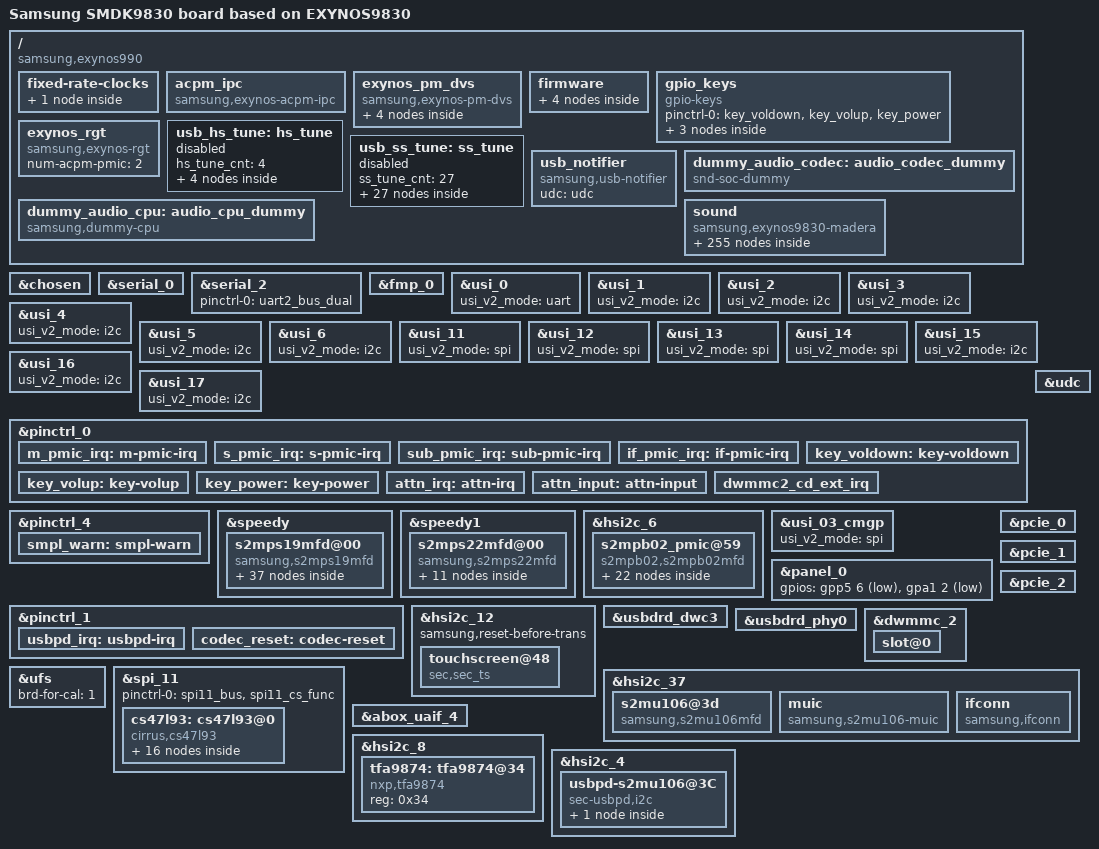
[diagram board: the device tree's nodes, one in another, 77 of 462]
/*
 * SAMSUNG EXYNOS9830 board device tree source
 *
 * Copyright (c) 2016 Samsung Electronics Co., Ltd.
 *		http://www.samsung.com
 *
 * This program is free software; you can redistribute it and/or modify
 * it under the terms of the GNU General Public License version 2 as
 * published by the Free Software Foundation.
*/

/dts-v1/;
/plugin/;
#include <dt-bindings/clock/exynos9830.h>
#include <dt-bindings/display/exynos-display.h>
#include "exynos9830-display-lcd.dtsi"
#include <dt-bindings/pci/pci.h>
#include "exynos9830-smdk9830-camera.dtsi"

#define BOARD_ID	0x0
#define BOARD_REV	0x0

/ {
	compatible = "samsung,exynos990", "samsung,SMDK990";
	board_id = <BOARD_ID>;
	board_rev = <BOARD_REV>;

	fragment@model {
		target-path = "/";
		__overlay__ {
			#address-cells = <2>;
			#size-cells = <1>;

			model = "Samsung SMDK9830 board based on EXYNOS9830";

			fixed-rate-clocks {
				oscclk {
					compatible = "samsung,exynos9830-oscclk";
					clock-frequency = <26000000>;
				};
			};

			acpm_ipc {
				compatible = "samsung,exynos-acpm-ipc";
				board-id = <BOARD_ID>;
				board-rev = <BOARD_REV>;
			};

			exynos_pm_dvs {
				compatible = "samsung,exynos-pm-dvs";
				vdd_lldo1 {
					regulator_name = "m_vdd_buck9";
					suspend_volt = <800000>;
					init_volt = <850000>;
					volt_range_step = <62500>;
				};

				vdd_lldo2 {
					regulator_name = "m_vdd_buck10";
					suspend_volt = <900000>;
					init_volt = <950000>;
					volt_range_step = <62500>;
				};

				vdd_lldo3 {
					regulator_name = "m_vdd_buck11";
					suspend_volt = <1250000>;
					init_volt = <1350000>;
					volt_range_step = <62500>;
				};
				vdd_mldo {
					regulator_name = "m_vdd_buck12";
					suspend_volt = <1850000>;
					init_volt = <2000000>;
					volt_range_step = <12500>;
				};
			};

			firmware {
				android: android {
					compatible = "android,firmware";
					vbmeta {
						compatible = "android,vbmeta";
						parts = "vbmeta,boot,system,vendor";
					};
					fstab {
						compatible = "android,fstab";
						vendor: vendor {
							compatible = "android,vendor";
							dev = "/dev/block/platform/13100000.ufs/by-name/vendor";
							type = "ext4";
							mnt_flags = "ro";
							fsmgr_flags = "wait,avb";
							status = "okay";
						};
					};
				};
			};

			gpio_keys {
				status = "okay";
				compatible = "gpio-keys";
				pinctrl-names = "default";
				pinctrl-0 = <&key_voldown &key_volup &key_power>;

				button@2 {
					label = "gpio-keys: KEY_VOLUMEDOWN";
					linux,code = <114>;
					gpios = <&gpa0 4 0xf>;
				};
				button@3 {
					label = "gpio-keys: KEY_VOLUMEUP";
					linux,code = <115>;
					gpios = <&gpa0 3 0xf>;
				};
				button@4 {
					label = "gpio-keys: KEY_POWER";
					linux,code = <116>;
					gpios = <&gpa2 4 0xf>;
					gpio-key,wakeup = <1>;
				};
			};

			exynos_rgt {
				compatible = "samsung,exynos-rgt";
				num-acpm-pmic = <2>;
			};

			usb_hs_tune:hs_tune {
				status = "disabled";
				hs_tune_cnt = <4>;
				/* value = <device host> */
				hs_tune1 {
					tune_name = "tx_pre_emp";
					tune_value = <0x3 0x3>;
				};

				hs_tune2 {
					tune_name = "tx_vref";
					tune_value = <0xc 0xc>;
				};

				hs_tune3 {
					tune_name = "rx_sqrx";
					tune_value = <0x5 0x5>;
				};

				hs_tune4 {
					tune_name = "utmi_clk";
					tune_value = <0x1 0x1>;
				};
			};

			usb_ss_tune:ss_tune {
				status = "disabled";
				ss_tune_cnt = <27>;
				/* value = <device host> */
				ss_tune1 {
					tune_name = "ssrx_sqhs_th_ssp";
					tune_value = <0x4 0x4>;
				};

				ss_tune2 {
					tune_name = "ssrx_lfps_th";
					tune_value = <0x2 0x2>;
				};

				ss_tune3 {
					tune_name = "ssrx_adap_coef_sel";
					tune_value = <0x1 0x1>;
				};

				ss_tune4 {
					tune_name = "ssrx_mf_eq_ctrl_ss";
					tune_value = <0x6 0x6>;
				};

				ss_tune5 {
					tune_name = "ssrx_mf_eq_ctrl_ssp";
					tune_value = <0x6 0x6>;
				};

				ss_tune6 {
					tune_name = "ssrx_hf_eq_ctrl_ss";
					tune_value = <0xe 0xe>;
				};

				ss_tune7 {
					tune_name = "ssrx_hf_eq_ctrl_ssp";
					tune_value = <0xe 0xe>;
				};

				ss_tune8 {
					tune_name = "ssrx_dfe_1tap_ctrl_ss";
					tune_value = <0x2 0x2>;
				};

				ss_tune9 {
					tune_name = "ssrx_dfe_1tap_ctrl_ssp";
					tune_value = <0x2 0x2>;
				};

				ss_tune10 {
					tune_name = "ssrx_dfe_2tap_ctrl_ss";
					tune_value = <0x0 0x0>;
				};

				ss_tune11 {
					tune_name = "ssrx_dfe_2tap_ctrl_ssp";
					tune_value = <0x0 0x0>;
				};

				ss_tune12 {
					tune_name = "ssrx_dfe_3tap_ctrl_ss";
					tune_value = <0x0 0x0>;
				};

				ss_tune13 {
					tune_name = "ssrx_dfe_3tap_ctrl_ssp";
					tune_value = <0x0 0x0>;
				};

				ss_tune14 {
					tune_name = "ssrx_dfe_4tap_ctrl_ss";
					tune_value = <0x0 0x0>;
				};

				ss_tune15 {
					tune_name = "ssrx_dfe_4tap_ctrl_ssp";
					tune_value = <0x0 0x0>;
				};

				ss_tune16 {
					tune_name = "ssrx_term_cal";
					tune_value = <0xb 0xb>;
				};

				ss_tune17 {
					tune_name = "sstx_amp_ss";
					tune_value = <0xb 0xb>;
				};

				ss_tune18 {
					tune_name = "sstx_deemp_ss";
					tune_value = <0x5 0x5>;
				};

				ss_tune19 {
					tune_name = "sstx_pre_shoot_ss";
					tune_value = <0x3 0x3>;
				};

				ss_tune20 {
					tune_name = "sstx_amp_ssp";
					tune_value = <0xb 0xb>;
				};

				ss_tune21 {
					tune_name = "sstx_deemp_ssp";
					tune_value = <0x5 0x5>;
				};

				ss_tune22 {
					tune_name = "sstx_pre_shoot_ssp";
					tune_value = <0x3 0x3>;
				};

				ss_tune23 {
					tune_name = "sstx_idrv_up";
					tune_value = <0x7 0x7>;
				};

				ss_tune24 {
					tune_name = "sstx_lfps_idrv_up";
					tune_value = <0x0 0x0>;
				};

				ss_tune25 {
					tune_name = "sstx_up_term";
					tune_value = <0x3 0x3>;
				};

				ss_tune26 {
					tune_name = "sstx_dn_term";
					tune_value = <0x3 0x3>;
				};

				ss_tune27 {
					tune_name = "rext_ovrd";
					tune_value = <0x0 0x0>; /* Use default */
				};
			};

			usb_notifier {
				compatible = "samsung,usb-notifier";
				udc = <&udc>;
			};

			dummy_audio_codec: audio_codec_dummy {
				compatible = "snd-soc-dummy";
				#sound-dai-cells = <0>;
			};

			dummy_audio_cpu: audio_cpu_dummy {
				compatible = "samsung,dummy-cpu";
				#sound-dai-cells = <0>;
			};

			sound {
				compatible = "samsung,exynos9830-madera";

				clock-names = "xclkout";
				clocks = <&clock OSC_AUD>;

				cirrus,sysclk = <1 4 98304000>;
				cirrus,dspclk = <8 4 147456000>;
				cirrus,fll1-refclk = <1 0 26000000 98304000>;

				cirrus,asyncclk = <2 5 90316800>;
				cirrus,fll2-refclk = <2 0 26000000 90316800>;

				samsung,routing = "HEADSETMIC", "MICBIAS2A",
					"IN1BL", "HEADSETMIC",
					"DMIC1", "MICBIAS1A",
					"IN3L", "DMIC1",
					"DMIC2", "MICBIAS1B",
					"IN4L", "DMIC2",
					"DMIC3", "MICBIAS1C",
					"IN2AL", "DMIC3",
					"DMIC4", "MICBIAS1D",
					"IN3R", "DMIC4",
					"RECEIVER", "HPOUT4L",
					"RECEIVER", "HPOUT4R",
					"HEADPHONE", "HPOUT2L",
					"HEADPHONE", "HPOUT2R",
					"SPEAKER", "OUTL",
					"AEC Loopback", "SPEAKER FB",
					"BLUETOOTH SPK", "ABOX UAIF3 Playback",
					"ABOX UAIF3 Capture", "BLUETOOTH MIC",
					"VOUTPUT", "ABOX UAIF5 Playback",
					"USB SPK", "ABOX USB Playback",
					"ABOX USB Capture", "USB MIC",
					"VTS Virtual Output", "VTS Virtual Output Mux",
					"PAD DPDM", "DMIC1",
					"PAD DPDM", "DMIC2",
					"PAD DPDM", "DMIC3",
					"PAD DPDM", "DMIC4";
				samsung,codec = <&vts>;
				samsung,prefix = "VTS";
				samsung,aux = <&abox_effect &abox_tplg>;

				rdma0 {
					cpu {
						sound-dai = <&abox_rdma_0 0>;
					};
					platform {
						sound-dai = <&abox_rdma_0 0>;
					};
					codec {
						sound-dai = <&dummy_audio_codec>;
					};
				};
				rdma1 {
					cpu {
						sound-dai = <&abox_rdma_1 0>;
					};
					platform {
						sound-dai = <&abox_rdma_1 0>;
					};
					codec {
						sound-dai = <&dummy_audio_codec>;
					};
				};
				rdma2 {
					cpu {
						sound-dai = <&abox_rdma_2 0>;
					};
					platform {
						sound-dai = <&abox_rdma_2 0>;
					};
					codec {
						sound-dai = <&dummy_audio_codec>;
					};
				};
				rdma3 {
					cpu {
						sound-dai = <&abox_rdma_3 0>;
					};
					platform {
						sound-dai = <&abox_rdma_3 0>;
					};
					codec {
						sound-dai = <&dummy_audio_codec>;
					};
				};
				rdma4 {
					cpu {
						sound-dai = <&abox_rdma_4 0>;
					};
					platform {
						sound-dai = <&abox_rdma_4 0>;
					};
					codec {
						sound-dai = <&dummy_audio_codec>;
					};
				};
				rdma5 {
					cpu {
						sound-dai = <&abox_rdma_5 0>;
					};
					platform {
						sound-dai = <&abox_rdma_5 0>;
					};
					codec {
						sound-dai = <&dummy_audio_codec>;
					};
				};
				rdma6 {
					cpu {
						sound-dai = <&abox_rdma_6 0>;
					};
					platform {
						sound-dai = <&abox_rdma_6 0>;
					};
					codec {
						sound-dai = <&dummy_audio_codec>;
					};
				};
				rdma7 {
					cpu {
						sound-dai = <&abox_rdma_7 0>;
					};
					platform {
						sound-dai = <&abox_rdma_7 0>;
					};
					codec {
						sound-dai = <&dummy_audio_codec>;
					};
				};
				rdma8 {
					cpu {
						sound-dai = <&abox_rdma_8 0>;
					};
					platform {
						sound-dai = <&abox_rdma_8 0>;
					};
					codec {
						sound-dai = <&dummy_audio_codec>;
					};
				};
				rdma9 {
					cpu {
						sound-dai = <&abox_rdma_9 0>;
					};
					platform {
						sound-dai = <&abox_rdma_9 0>;
					};
					codec {
						sound-dai = <&dummy_audio_codec>;
					};
				};
				rdma10 {
					cpu {
						sound-dai = <&abox_rdma_10 0>;
					};
					platform {
						sound-dai = <&abox_rdma_10 0>;
					};
					codec {
						sound-dai = <&dummy_audio_codec>;
					};
				};
				rdma11 {
					cpu {
						sound-dai = <&abox_rdma_11 0>;
					};
					platform {
						sound-dai = <&abox_rdma_11 0>;
					};
					codec {
						sound-dai = <&dummy_audio_codec>;
					};
				};
				wdma0 {
					cpu {
						sound-dai = <&abox_wdma_0 0>;
					};
					platform {
						sound-dai = <&abox_wdma_0 0>;
					};
					codec {
						sound-dai = <&dummy_audio_codec>;
					};
				};
				wdma1 {
					cpu {
						sound-dai = <&abox_wdma_1 0>;
					};
					platform {
						sound-dai = <&abox_wdma_1 0>;
					};
					codec {
						sound-dai = <&dummy_audio_codec>;
					};
				};
				wdma2 {
					cpu {
						sound-dai = <&abox_wdma_2 0>;
					};
					platform {
						sound-dai = <&abox_wdma_2 0>;
					};
					codec {
						sound-dai = <&dummy_audio_codec>;
					};
				};
				wdma3 {
					cpu {
						sound-dai = <&abox_wdma_3 0>;
					};
					platform {
						sound-dai = <&abox_wdma_3 0>;
					};
					codec {
						sound-dai = <&dummy_audio_codec>;
					};
				};
				wdma4 {
					cpu {
						sound-dai = <&abox_wdma_4 0>;
					};
					platform {
						sound-dai = <&abox_wdma_4 0>;
					};
					codec {
						sound-dai = <&dummy_audio_codec>;
					};
				};
				vts0 {
					cpu {
						sound-dai = <&vts 0>;
					};
					codec {
						sound-dai = <&dummy_audio_codec>;
					};
				};
				vts1 {
					cpu {
						sound-dai = <&vts 1>;
					};
					codec {
						sound-dai = <&dummy_audio_codec>;
					};
				};
				dp0_audio {
					cpu {
						sound-dai = <&displayport_adma 0>;
					};
					codec {
						sound-dai = <&dummy_audio_codec>;
					};
				};
				dp1_audio {
					cpu {
						sound-dai = <&displayport_adma 1 >;
					};
					codec {
						sound-dai = <&dummy_audio_codec>;
					};
				};
				dual0 {
					cpu {
						sound-dai = <&abox_dual_0>;
					};
					platform {
						sound-dai = <&abox_dual_0>;
					};
					codec {
						sound-dai = <&dummy_audio_codec>;
					};
				};
				dual1 {
					cpu {
						sound-dai = <&abox_dual_1>;
					};
					platform {
						sound-dai = <&abox_dual_1>;
					};
					codec {
						sound-dai = <&dummy_audio_codec>;
					};
				};
				dual2 {
					cpu {
						sound-dai = <&abox_dual_2>;
					};
					platform {
						sound-dai = <&abox_dual_2>;
					};
					codec {
						sound-dai = <&dummy_audio_codec>;
					};
				};
				dual3 {
					cpu {
						sound-dai = <&abox_dual_3>;
					};
					platform {
						sound-dai = <&abox_dual_3>;
					};
					codec {
						sound-dai = <&dummy_audio_codec>;
					};
				};
				dual4 {
					cpu {
						sound-dai = <&abox_dual_4>;
					};
					platform {
						sound-dai = <&abox_dual_4>;
					};
					codec {
						sound-dai = <&dummy_audio_codec>;
					};
				};
				ddma0 {
					cpu {
						sound-dai = <&abox_ddma_0>;
					};
					platform {
						sound-dai = <&abox_ddma_0>;
					};
					codec {
						sound-dai = <&dummy_audio_codec>;
					};
				};
				ddma1 {
					cpu {
						sound-dai = <&abox_ddma_1>;
					};
					platform {
						sound-dai = <&abox_ddma_1>;
					};
					codec {
						sound-dai = <&dummy_audio_codec>;
					};
				};
				ddma2 {
					cpu {
						sound-dai = <&abox_ddma_2>;
					};
					platform {
						sound-dai = <&abox_ddma_2>;
					};
					codec {
						sound-dai = <&dummy_audio_codec>;
					};
				};
				ddma3 {
					cpu {
						sound-dai = <&abox_ddma_3>;
					};
					platform {
						sound-dai = <&abox_ddma_3>;
					};
					codec {
						sound-dai = <&dummy_audio_codec>;
					};
				};
				ddma4 {
					cpu {
						sound-dai = <&abox_ddma_4>;
					};
					platform {
						sound-dai = <&abox_ddma_4>;
					};
					codec {
						sound-dai = <&dummy_audio_codec>;
					};
				};
				ddma5 {
					cpu {
						sound-dai = <&abox_ddma_5>;
					};
					platform {
						sound-dai = <&abox_ddma_5>;
					};
					codec {
						sound-dai = <&dummy_audio_codec>;
					};
				};
				uaif0 {
					format = "i2s";
					cpu {
						sound-dai = <&abox_uaif_0>;
					};
					codec {
						sound-dai = <&cs47l93 0>;
					};
				};
				uaif1 {
					format = "i2s";
					cpu {
						sound-dai = <&abox_uaif_1>;
					};
					codec {
						sound-dai = <&cs47l93 2>;
					};
				};
				uaif2 {
					format = "i2s";
					cpu {
						sound-dai = <&abox_uaif_2>;
					};
					codec {
						sound-dai = <&tfa9874 0>;
					};
				};
				uaif3 {
					format = "i2s";
					cpu {
						sound-dai = <&abox_uaif_3>;
					};
					codec {
						sound-dai = <&dummy_audio_codec>;
					};
				};
				uaif4 {
					format = "i2s";
					cpu {
						sound-dai = <&abox_uaif_4>;
					};
					codec {
						sound-dai = <&dummy_audio_codec>;
					};
				};
				uaif5 {
					format = "dsp_a";
					cpu {
						sound-dai = <&abox_uaif_5>;
					};
					codec {
						sound-dai = <&dummy_audio_codec>;
					};
				};
				uaif6 {
					format = "dsp_a";
					bitclock-master;
					bitclock-inversion;
					frame-master;

					cpu {
						sound-dai = <&abox_uaif_6>;
					};
					codec {
						sound-dai = <&vts_s_lif 0>;
					};
				};
				dsif0 {
					format = "pdm";
					cpu {
						sound-dai = <&abox_dsif>;
					};
					codec {
						sound-dai = <&dummy_audio_codec>;
					};
				};
				sifs0 {
					cpu {
						sound-dai = <&abox 0>;
					};
					codec {
						sound-dai = <&dummy_audio_codec>;
					};
				};
				sifs1 {
					cpu {
						sound-dai = <&abox 1>;
					};
					codec {
						sound-dai = <&dummy_audio_codec>;
					};
				};
				sifs2 {
					cpu {
						sound-dai = <&abox 2>;
					};
					codec {
						sound-dai = <&dummy_audio_codec>;
					};
				};
				sifs3 {
					cpu {
						sound-dai = <&abox 3>;
					};
					codec {
						sound-dai = <&dummy_audio_codec>;
					};
				};
				sifs4 {
					cpu {
						sound-dai = <&abox 4>;
					};
					codec {
						sound-dai = <&dummy_audio_codec>;
					};
				};
				sifs5 {
					cpu {
						sound-dai = <&abox 5>;
					};
					codec {
						sound-dai = <&dummy_audio_codec>;
					};
				};
				nsrc0 {
					cpu {
						sound-dai = <&abox 6>;
					};
					codec {
						sound-dai = <&dummy_audio_codec>;
					};
				};
				nsrc1 {
					cpu {
						sound-dai = <&abox 7>;
					};
					codec {
						sound-dai = <&dummy_audio_codec>;
					};
				};
				nsrc2 {
					cpu {
						sound-dai = <&abox 8>;
					};
					codec {
						sound-dai = <&dummy_audio_codec>;
					};
				};
				nsrc3 {
					cpu {
						sound-dai = <&abox 9>;
					};
					codec {
						sound-dai = <&dummy_audio_codec>;
					};
				};
				nsrc4 {
					cpu {
						sound-dai = <&abox 10>;
					};
					codec {
						sound-dai = <&dummy_audio_codec>;
					};
				};
				rdma0_be {
					cpu {
						sound-dai = <&abox_rdma_0 1>;
					};
					platform {
						sound-dai = <&abox_rdma_0 1>;
					};
					codec {
						sound-dai = <&dummy_audio_codec>;
					};
				};
				rdma1_be {
					cpu {
						sound-dai = <&abox_rdma_1 1>;
					};
					platform {
						sound-dai = <&abox_rdma_1 1>;
					};
					codec {
						sound-dai = <&dummy_audio_codec>;
					};
				};
				rdma2_be {
					cpu {
						sound-dai = <&abox_rdma_2 1>;
					};
					platform {
						sound-dai = <&abox_rdma_2 1>;
					};
					codec {
						sound-dai = <&dummy_audio_codec>;
					};
				};
				rdma3_be {
					cpu {
						sound-dai = <&abox_rdma_3 1>;
					};
					platform {
						sound-dai = <&abox_rdma_3 1>;
					};
					codec {
						sound-dai = <&dummy_audio_codec>;
					};
				};
				rdma4_be {
					cpu {
						sound-dai = <&abox_rdma_4 1>;
					};
					platform {
						sound-dai = <&abox_rdma_4 1>;
					};
					codec {
						sound-dai = <&dummy_audio_codec>;
					};
				};
				rdma5_be {
					cpu {
						sound-dai = <&abox_rdma_5 1>;
					};
					platform {
						sound-dai = <&abox_rdma_5 1>;
					};
					codec {
						sound-dai = <&dummy_audio_codec>;
					};
				};
				rdma6_be {
					cpu {
						sound-dai = <&abox_rdma_6 1>;
					};
					platform {
						sound-dai = <&abox_rdma_6 1>;
					};
					codec {
						sound-dai = <&dummy_audio_codec>;
					};
				};
				rdma7_be {
					cpu {
						sound-dai = <&abox_rdma_7 1>;
					};
					platform {
						sound-dai = <&abox_rdma_7 1>;
					};
					codec {
						sound-dai = <&dummy_audio_codec>;
					};
				};
				rdma8_be {
					cpu {
						sound-dai = <&abox_rdma_8 1>;
					};
					platform {
						sound-dai = <&abox_rdma_8 1>;
					};
					codec {
						sound-dai = <&dummy_audio_codec>;
					};
				};
				rdma9_be {
					cpu {
						sound-dai = <&abox_rdma_9 1>;
					};
					platform {
						sound-dai = <&abox_rdma_9 1>;
					};
					codec {
						sound-dai = <&dummy_audio_codec>;
					};
				};
				rdma10_be {
					cpu {
						sound-dai = <&abox_rdma_10 1>;
					};
					platform {
						sound-dai = <&abox_rdma_10 1>;
					};
					codec {
						sound-dai = <&dummy_audio_codec>;
					};
				};
				rdma11_be {
					cpu {
						sound-dai = <&abox_rdma_11 1>;
					};
					platform {
						sound-dai = <&abox_rdma_11 1>;
					};
					codec {
						sound-dai = <&dummy_audio_codec>;
					};
				};
				wdma0_be {
					cpu {
						sound-dai = <&abox_wdma_0 1>;
					};
					platform {
						sound-dai = <&abox_wdma_0 1>;
					};
					codec {
						sound-dai = <&dummy_audio_codec>;
					};
				};
				wdma1_be {
					cpu {
						sound-dai = <&abox_wdma_1 1>;
					};
					platform {
						sound-dai = <&abox_wdma_1 1>;
					};
					codec {
						sound-dai = <&dummy_audio_codec>;
					};
				};
				wdma2_be {
					cpu {
						sound-dai = <&abox_wdma_2 1>;
					};
					platform {
						sound-dai = <&abox_wdma_2 1>;
					};
					codec {
						sound-dai = <&dummy_audio_codec>;
					};
				};
				wdma3_be {
					cpu {
						sound-dai = <&abox_wdma_3 1>;
					};
					platform {
						sound-dai = <&abox_wdma_3 1>;
					};
					codec {
						sound-dai = <&dummy_audio_codec>;
					};
				};
				wdma4_be {
					cpu {
						sound-dai = <&abox_wdma_4 1>;
					};
					platform {
						sound-dai = <&abox_wdma_4 1>;
					};
					codec {
						sound-dai = <&dummy_audio_codec>;
					};
				};
				usb {
					cpu {
						sound-dai = <&abox 16>;
					};
					codec {
						sound-dai = <&dummy_audio_codec>;
					};
				};
				debug-trace@1 {
					cpu {
						sound-dai = <&cs47l93 6>;
					};
					codec {
						sound-dai = <&cs47l93 7>;
					};
				};
			};
		}; /* end of __overlay__ */
	}; /* end of fragment */
}; /* end of root */

&chosen {
	bootargs_ext = "console=ram skip_initramfs rootwait ro init=/init";
};

&serial_0 {
	status = "okay";
};

&serial_2 {
	pinctrl-0 = <&uart2_bus_dual>;
};

&fmp_0 {
	exynos,block-type = "sda";
	exynos,fips-block_offset = <5>;
};

/* USI_00 */
&usi_0 {
	usi_v2_mode = "uart";
	status = "okay";
};

/* USI_01 */
&usi_1 {
	usi_v2_mode = "i2c";
	status = "okay";
};

/* USI_02 */
&usi_2 {
	usi_v2_mode = "i2c";
	status = "okay";
};

/* USI_02 */
&usi_2 {
	usi_v2_mode = "i2c";
	status = "okay";
};

/* USI_03 */
&usi_3 {
	usi_v2_mode = "i2c";
	status = "okay";
};

/* USI_04 */
&usi_4 {
	usi_v2_mode = "i2c";
	status = "okay";
};

/* USI_05 */
&usi_5 {
	usi_v2_mode = "i2c";
	status = "okay";
};

/* USI_06 */
&usi_6 {
	usi_v2_mode = "i2c";
	status = "okay";
};

/* USI_11 */
&usi_11 {
	usi_v2_mode = "spi";
	status = "okay";
};

/* USI_12 */
&usi_12 {
	usi_v2_mode = "spi";
	status = "okay";
};

/* USI_13 */
&usi_13 {
	usi_v2_mode = "spi";
	status = "okay";
};

/* USI_14 */
&usi_14 {
	usi_v2_mode = "spi";
	status = "okay";
};

/* USI_15 */
&usi_15 {
	usi_v2_mode = "i2c";
	status = "okay";
};

/* USI_16 */
&usi_16 {
	usi_v2_mode = "i2c";
	status = "okay";
};

/* USI_17 */
&usi_17 {
	usi_v2_mode = "i2c";
	status = "okay";
};

&pinctrl_0 {
	m_pmic_irq: m-pmic-irq {
		samsung,pins = "gpa0-1";
		samsung,pin-pud = <3>;
		samsung,pin-drv = <3>;
	};

	s_pmic_irq: s-pmic-irq {
		samsung,pins = "gpa0-2";
		samsung,pin-pud = <3>;
		samsung,pin-drv = <3>;
	};

	sub_pmic_irq: sub-pmic-irq {
		samsung,pins = "gpa1-3";
		samsung,pin-function = <0>;
		samsung,pin-pud = <0>;
		samsung,pin-drv = <0>;
	};

	if_pmic_irq: if-pmic-irq {
		samsung,pins = "gpa2-0";
		samsung,pin-function = <0>;
		samsung,pin-pud = <0>;
		samsung,pin-drv = <0>;
	};
};

&pinctrl_4 {
	smpl_warn: smpl-warn {
		samsung,pins = "gpg0-1";
		samsung,pin-function = <15>;
		samsung,pin-pud = <0>;
		samsung,pin-drv = <0>;
	};
};

&speedy {
	#address-cells = <1>;
	#size-cells = <0>;
	status = "okay";
	s2mps19mfd@00 {
		compatible = "samsung,s2mps19mfd";
		acpm-ipc-channel = <2>;
		acpm-speedy-channel = <0>;
		i2c-speedy-address;
		s2mps19,wakeup = "enabled";
		s2mps19,irq-gpio = <&gpa0 1 0>;
		reg = <0x00>;
		interrupts = <1 0 0>;
		interrupt-parent = <&gpa0>;
		pinctrl-names = "default";
		pinctrl-0 = <&m_pmic_irq &smpl_warn>;
		gpios = <&gpg0 1 0>;
		smpl_warn_en = <1>; /* 1 : enable , 0 : disable */
		/* range of smpl_warn_vth */
		/* 0x00 : 2.1V, 0x20 : 2.3V, 0x40 : 2.5V, 0x60 : 2.7V 0x80 : 2.9V */
		/* 0xA0 : 3.1V, 0xC0 : 3.3V, 0xE0 : 3.5V */
		smpl_warn_vth = <0x80>;
		/* LowBat_Hys[4:3] 00(100mV), 01(200mV), 10(300mV), 11(400mV) */
		smpl_warn_hys = <0x00>;
		ocp_warn1_en = <1>; /* 1 : enable, 0 : disable */
		ocp_warn1_cnt = <0>; /* ocp warn reset timing control, 0 : 2 clock, 1 : 32 clock */
		ocp_warn1_dvs_mask = <0>; /* ocp warn mask when dvs, 0 : not masked, 1 : masked  */
		ocp_warn1_lv = <0x0>; /* step : -250mA */
		ocp_warn2_en = <0>; /* 1 : enable, 0 : disable */
		ocp_warn2_cnt = <0>; /* ocp warn reset timing control, 0 : 2 clock, 1 : 32 clock */
		ocp_warn2_dvs_mask = <0>; /* ocp warn mask when dvs, 0 : not masked, 1 : masked  */
		ocp_warn2_lv = <0x0>; /* step : -250mA */
		adc_mode = <1>; /* 0 : disable, 1 : current meter, 2 : power meter */
		adc_sync_mode = <2>; /* 1 : sync mode, 2 : async mode */
		/* RTC: wtsr/smpl */
		wtsr_en = "enabled"; /* enable */
		smpl_en = "enabled"; /* enable */
		wtsr_timer_val = <3>;	/* 1000ms */
		smpl_timer_val = <4>;	/* 500ms */
		sub_smpl_en = "enabled"; /* enable */
		check_jigon = <0>; /* do not check jigon */
		/* RTC: If it's first boot, reset rtc to 1/1/2017 12:00:00(Sun) */
		init_time,sec = <0>;
		init_time,min = <0>;
		init_time,hour = <12>;
		init_time,mday = <1>;
		init_time,mon = <0>;
		init_time,year = <117>;
		init_time,wday = <0>;

		regulators {
			buck1_reg: BUCK1M {
				regulator-name = "m_vdd_buck1";
				regulator-min-microvolt = <450000>;
				regulator-max-microvolt = <1100000>;
				regulator-always-on;
				regulator-ramp-delay = <6000>;
				regulator-initial-mode = <2>;
			};

			buck2_reg: BUCK2M {
				regulator-name = "m_vdd_buck2";
				regulator-min-microvolt = <450000>;
				regulator-max-microvolt = <1300000>;
				regulator-always-on;
				regulator-ramp-delay = <6000>;
				regulator-initial-mode = <2>;
			};

			buck3_reg: BUCK3M {
				regulator-name = "m_vdd_buck3";
				regulator-min-microvolt = <450000>;
				regulator-max-microvolt = <1300000>;
				regulator-always-on;
				regulator-ramp-delay = <6000>;
				regulator-initial-mode = <2>;
			};

			buck5_reg: BUCK5M {
				regulator-name = "m_vdd_buck5";
				regulator-min-microvolt = <450000>;
				regulator-max-microvolt = <1100000>;
				regulator-always-on;
				regulator-ramp-delay = <6000>;
				regulator-initial-mode = <2>;
			};

			buck6_reg: BUCK6M {
				regulator-name = "m_vdd_buck6";
				regulator-min-microvolt = <450000>;
				regulator-max-microvolt = <1100000>;
				regulator-always-on;
				regulator-ramp-delay = <6000>;
				regulator-initial-mode = <1>;
			};

			buck7_reg: BUCK7M {
				regulator-name = "m_vdd_buck7";
				regulator-min-microvolt = <450000>;
				regulator-max-microvolt = <1300000>;
				regulator-always-on;
				regulator-ramp-delay = <6000>;
				regulator-initial-mode = <2>;
			};

			buck8_reg: BUCK8M {
				regulator-name = "m_vdd_buck8";
				regulator-min-microvolt = <450000>;
				regulator-max-microvolt = <950000>;
				regulator-always-on;
				regulator-ramp-delay = <6000>;
				regulator-initial-mode = <2>;
			};

			buck9_reg: BUCK9M {
				regulator-name = "m_vdd_buck9";
				regulator-min-microvolt = <800000>;
				regulator-max-microvolt = <1300000>;
				regulator-always-on;
				regulator-ramp-delay = <6000>;
				regulator-initial-mode = <3>;
			};

			buck10_reg: BUCK10M {
				regulator-name = "m_vdd_buck10";
				regulator-min-microvolt = <800000>;
				regulator-max-microvolt = <1300000>;
				regulator-always-on;
				regulator-ramp-delay = <6000>;
				regulator-initial-mode = <3>;
			};

			buck11_reg: BUCK11M {
				regulator-name = "m_vdd_buck11";
				regulator-min-microvolt = <1100000>;
				regulator-max-microvolt = <1500000>;
				regulator-always-on;
				regulator-ramp-delay = <6000>;
				regulator-initial-mode = <3>;
			};

			buck12_reg: BUCK12M {
				regulator-name = "m_vdd_buck12";
				regulator-min-microvolt = <1750000>;
				regulator-max-microvolt = <2150000>;
				regulator-always-on;
				regulator-ramp-delay = <6000>;
				regulator-initial-mode = <3>;
			};

			ldo1_reg: LDO1M {
				regulator-name = "m_vdd_ldo1";
				regulator-min-microvolt = <700000>;
				regulator-max-microvolt = <950000>;
				regulator-always-on;
				regulator-ramp-delay = <12000>;
				regulator-initial-mode = <3>;
			};

			ldo2_reg: LDO2M {
				regulator-name = "vqmmc";
				regulator-min-microvolt = <1700000>;
				regulator-max-microvolt = <3300000>;
				regulator-ramp-delay = <12000>;
				regulator-initial-mode = <3>;
			};

			ldo3_reg: LDO3M {
				regulator-name = "m_vdd_ldo3";
				regulator-min-microvolt = <700000>;
				regulator-max-microvolt = <1100000>;
				regulator-always-on;
				regulator-ramp-delay = <12000>;
				regulator-initial-mode = <1>;
			};

			ldo4_reg: LDO4M {
				regulator-name = "m_vdd_ldo4";
				regulator-min-microvolt = <1600000>;
				regulator-max-microvolt = <1950000>;
				regulator-always-on;
				regulator-ramp-delay = <12000>;
				regulator-initial-mode = <1>;
			};

			ldo5_reg: LDO5M {
				regulator-name = "m_vdd_ldo5";
				regulator-min-microvolt = <450000>;
				regulator-max-microvolt = <1100000>;
				regulator-always-on;
				regulator-ramp-delay = <12000>;
				regulator-initial-mode = <1>;
			};

			ldo6_reg: LDO6M {
				regulator-name = "m_vdd_ldo6";
				regulator-min-microvolt = <450000>;
				regulator-max-microvolt = <950000>;
				regulator-always-on;
				regulator-ramp-delay = <12000>;
				regulator-initial-mode = <1>;
			};

			ldo9_reg: LDO9M {
				regulator-name = "m_vdd_ldo9";
				regulator-min-microvolt = <700000>;
				regulator-max-microvolt = <1300000>;
				regulator-always-on;
				regulator-ramp-delay = <12000>;
				regulator-initial-mode = <1>;
			};

			ldo10_reg: LDO10M {
				regulator-name = "m_vdd_ldo10";
				regulator-min-microvolt = <700000>;
				regulator-max-microvolt = <1100000>;
				regulator-boot-on;
				regulator-ramp-delay = <12000>;
				regulator-initial-mode = <1>;
			};

			ldo11_reg: LDO11M {
				regulator-name = "m_vdd_ldo11";
				regulator-min-microvolt = <1600000>;
				regulator-max-microvolt = <1950000>;
				regulator-boot-on;
				regulator-ramp-delay = <12000>;
				regulator-initial-mode = <1>;
			};

			ldo12_reg: LDO12M {
				regulator-name = "m_vdd_ldo12";
				regulator-min-microvolt = <1700000>;
				regulator-max-microvolt = <3350000>;
				regulator-boot-on;
				regulator-ramp-delay = <12000>;
				regulator-initial-mode = <1>;
			};

			ldo15_reg: LDO15M {
				regulator-name = "vmmc";
				regulator-min-microvolt = <2500000>;
				regulator-max-microvolt = <3300000>;
				regulator-ramp-delay = <12000>;
				regulator-initial-mode = <3>;
			};

			ldo16_reg: LDO16M {
				regulator-name = "m_vdd_ldo16";
				regulator-min-microvolt = <2500000>;
				regulator-max-microvolt = <3300000>;
				regulator-always-on;
				regulator-ramp-delay = <12000>;
				regulator-initial-mode = <3>;
			};

			ldo17_reg: LDO17M {
				regulator-name = "m_vdd_ldo17";
				regulator-min-microvolt = <1600000>;
				regulator-max-microvolt = <2200000>;
				regulator-always-on;
				regulator-ramp-delay = <12000>;
				regulator-initial-mode = <3>;
			};

			ldo18_reg: LDO18M {
				regulator-name = "m_vdd_ldo18";
				regulator-min-microvolt = <700000>;
				regulator-max-microvolt = <1300000>;
				regulator-ramp-delay = <12000>;
				regulator-initial-mode = <3>;
			};

			ldo19_reg: LDO19M {
				regulator-name = "m_vdd_ldo19";
				regulator-min-microvolt = <1600000>;
				regulator-max-microvolt = <2200000>;
				regulator-always-on;
				regulator-ramp-delay = <12000>;
				regulator-initial-mode = <3>;
			};

			ldo20_reg: LDO20M {
				regulator-name = "m_vdd_ldo20";
				regulator-min-microvolt = <2500000>;
				regulator-max-microvolt = <3300000>;
				regulator-always-on;
				regulator-ramp-delay = <12000>;
				regulator-initial-mode = <3>;
			};

			ldo21_reg: LDO21M {
				regulator-name = "m_vdd_ldo21";
				regulator-min-microvolt = <1600000>;
				regulator-max-microvolt = <2200000>;
				regulator-always-on;
				regulator-ramp-delay = <12000>;
				regulator-initial-mode = <3>;
			};

			ldo22_reg: LDO22M {
				regulator-name = "m_vdd_ldo22";
				regulator-min-microvolt = <1600000>;
				regulator-max-microvolt = <2200000>;
				regulator-always-on;
				regulator-ramp-delay = <12000>;
				regulator-initial-mode = <3>;
			};

			ldo23_reg: LDO23M {
				regulator-name = "VDDD_1.2V_FRONTSUB";
				regulator-min-microvolt = <700000>;
				regulator-max-microvolt = <1300000>;
				regulator-ramp-delay = <12000>;
				regulator-initial-mode = <3>;
			};

			ldo24_reg: LDO24M {
				regulator-name = "VDDA_2.8V_FRONTSUB";
				regulator-min-microvolt = <2500000>;
				regulator-max-microvolt = <3300000>;
				regulator-ramp-delay = <12000>;
				regulator-initial-mode = <3>;
			};

			ldo25_reg: LDO25M {
				regulator-name = "VDDIO_1.8V_FRONTSUB";
				regulator-min-microvolt = <1600000>;
				regulator-max-microvolt = <2200000>;
				regulator-ramp-delay = <12000>;
				regulator-initial-mode = <3>;
			};

			ldo26_reg: LDO26M {
				regulator-name = "m_vdd_ldo26";
				regulator-min-microvolt = <1800000>;
				regulator-max-microvolt = <2200000>;
				regulator-always-on;
				regulator-ramp-delay = <12000>;
				regulator-initial-mode = <3>;
			};

			ldo27_reg: LDO27M {
				regulator-name = "m_vdd_ldo27";
				regulator-min-microvolt = <2500000>;
				regulator-max-microvolt = <3300000>;
				regulator-always-on;
				regulator-ramp-delay = <12000>;
				regulator-initial-mode = <3>;
			};

			ldo28_reg: LDO28M {
				regulator-name = "m_vdd_ldo28";
				regulator-min-microvolt = <1600000>;
				regulator-max-microvolt = <2200000>;
				regulator-always-on;
				regulator-ramp-delay = <12000>;
				regulator-initial-mode = <3>;
			};

			ldo29_reg: LDO29M {
				regulator-name = "m_vdd_ldo29";
				regulator-min-microvolt = <2500000>;
				regulator-max-microvolt = <3300000>;
				regulator-always-on;
				regulator-ramp-delay = <12000>;
				regulator-initial-mode = <3>;
			};
		};
	};
};

&speedy1 {
	#address-cells = <1>;
	#size-cells = <0>;
	status = "okay";
	s2mps22mfd@00 {
		compatible = "samsung,s2mps22mfd";
		acpm-ipc-channel = <2>;
		acpm-speedy-channel = <1>;
		i2c-speedy-address;
		s2mps22,wakeup = "enabled";
		s2mps22,irq-gpio = <&gpa0 2 0>;
		reg = <0x00>;
		interrupts = <1 0 0>;
		interrupt-parent = <&gpa0>;
		pinctrl-names = "default";
		pinctrl-0 = <&s_pmic_irq>;
		adc_mode = <1>; /* 0 : disable, 1 : current meter, 2 : power meter */
		adc_sync_mode = <2>; /* 1 : sync mode, 2 : async mode */
		wtsr_en = <1>; /* 0 : disable, 1 : enable */

		regulators {
			s_buck1_reg: BUCK1S {
				regulator-name = "s_vdd_buck1";
				regulator-min-microvolt = <450000>;
				regulator-max-microvolt = <950000>;
				regulator-always-on;
				regulator-ramp-delay = <6000>;
				regulator-initial-mode = <1>;
			};

			s_buck2_reg: BUCK2S {
				regulator-name = "s_vdd_buck2";
				regulator-min-microvolt = <450000>;
				regulator-max-microvolt = <1100000>;
				regulator-always-on;
				regulator-ramp-delay = <6000>;
				regulator-initial-mode = <1>;
			};

			s_buck3_reg: BUCK3S {
				regulator-name = "s_vdd_buck3";
				regulator-min-microvolt = <450000>;
				regulator-max-microvolt = <1300000>;
				regulator-always-on;
				regulator-ramp-delay = <6000>;
				regulator-initial-mode = <1>;
			};

			s_buck4_reg: BUCK4S {
				regulator-name = "s_vdd_buck4";
				regulator-min-microvolt = <900000>;
				regulator-max-microvolt = <1300000>;
				regulator-always-on;
				regulator-ramp-delay = <6000>;
				regulator-initial-mode = <3>;
			};

			s_ldo1_reg: LDO1S {
				regulator-name = "s_vdd_ldo1";
				regulator-min-microvolt = <450000>;
				regulator-max-microvolt = <950000>;
				regulator-always-on;
				regulator-ramp-delay = <12000>;
				regulator-initial-mode = <1>;
			};

			s_ldo2_reg: LDO2S {
				regulator-name = "s_vdd_ldo2";
				regulator-min-microvolt = <450000>;
				regulator-max-microvolt = <950000>;
				regulator-always-on;
				regulator-ramp-delay = <12000>;
				regulator-initial-mode = <1>;
			};

			s_ldo3_reg: LDO3S {
				regulator-name = "s_vdd_ldo3";
				regulator-min-microvolt = <450000>;
				regulator-max-microvolt = <1300000>;
				regulator-always-on;
				regulator-ramp-delay = <12000>;
				regulator-initial-mode = <1>;
			};

			s_ldo4_reg: LDO4S {
				regulator-name = "s_vdd_ldo4";
				regulator-min-microvolt = <1600000>;
				regulator-max-microvolt = <1950000>;
				regulator-always-on;
				regulator-ramp-delay = <12000>;
				regulator-initial-mode = <3>;
			};

			s_ldo5_reg: LDO5S {
				regulator-name = "s_vdd_ldo5";
				regulator-min-microvolt = <700000>;
				regulator-max-microvolt = <1100000>;
				regulator-always-on;
				regulator-ramp-delay = <12000>;
				regulator-initial-mode = <1>;
			};

			s_ldo6_reg: LDO6S {
				regulator-name = "s_vdd_ldo6";
				regulator-min-microvolt = <1600000>;
				regulator-max-microvolt = <1950000>;
				regulator-always-on;
				regulator-ramp-delay = <12000>;
				regulator-initial-mode = <1>;
			};
		};
	};
};

&hsi2c_6 {
	#address-cells = <1>;
	#size-cells = <0>;
	status = "okay";
	s2mpb02_pmic@59 {
		compatible = "s2mpb02,s2mpb02mfd";
		reg = <0x59>;

		s2mpb02,wakeup;
		pinctrl-names = "default";
		pinctrl-0 = <&sub_pmic_irq>;

		regulators {
			_buck1_reg: s2mpb02-buck1 {
				regulator-name = "S2MPB02_BUCK1";
				regulator-min-microvolt = <600000>;
				regulator-max-microvolt = <1700000>;
				regulator-always-on;
				regulator-boot-on;
			};

			_buck2_reg: s2mpb02-buck2 {
				regulator-name = "S2MPB02_BUCK2";
				regulator-min-microvolt = <1050000>;
				regulator-max-microvolt = <1050000>;
			};

			_buckboost_reg: s2mpb02-bb {
				regulator-name = "S2MPB02_BB";
				regulator-min-microvolt = <2600000>;
				regulator-max-microvolt = <4000000>;
				regulator-always-on;
				regulator-boot-on;
			};

			_ldo1_reg: s2mpb02-ldo1 {
				regulator-name = "S2MPB02_LDO1";
				regulator-min-microvolt = <900000>;
				regulator-max-microvolt = <900000>;
				regulator-always-on;
			};

			_ldo2_reg: s2mpb02-ldo2 {
				regulator-name = "S2MPB02_LDO2";
				regulator-min-microvolt = <1000000>;
				regulator-max-microvolt = <1000000>;
			};

			_ldo3_reg: s2mpb02-ldo3 {
				regulator-name = "S2MPB02_LDO3";
				regulator-min-microvolt = <1200000>;
				regulator-max-microvolt = <1200000>;
			};

			_ldo4_reg: s2mpb02-ldo4 {
				regulator-name = "S2MPB02_LDO4";
				regulator-min-microvolt = <1200000>;
				regulator-max-microvolt = <1200000>;
			};

			_ldo5_reg: s2mpb02-ldo5 {
				regulator-name = "S2MPB02_LDO5";
				regulator-min-microvolt = <1200000>;
				regulator-max-microvolt = <1200000>;
			};

			_ldo6_reg: s2mpb02-ldo6 {
				regulator-name = "S2MPB02_LDO6";
				regulator-min-microvolt = <1800000>;
				regulator-max-microvolt = <1800000>;
				regulator-always-on;
				regulator-boot-on;
			};

			_ldo7_reg: s2mpb02-ldo7 {
				regulator-name = "S2MPB02_LDO7";
				regulator-min-microvolt = <1800000>;
				regulator-max-microvolt = <1800000>;
			};

			_ldo8_reg: s2mpb02-ldo8 {
				regulator-name = "S2MPB02_LDO8";
				regulator-min-microvolt = <1800000>;
				regulator-max-microvolt = <1800000>;
			};

			_ldo9_reg: s2mpb02-ldo9 {
				regulator-name = "S2MPB02_LDO9";
				regulator-min-microvolt = <1800000>;
				regulator-max-microvolt = <1800000>;
				regulator-always-on;
				regulator-boot-on;
			};

			_ldo10_reg: s2mpb02-ldo10 {
				regulator-name = "S2MPB02_LDO10";
				regulator-min-microvolt = <1800000>;
				regulator-max-microvolt = <1800000>;
			};

			_ldo11_reg: s2mpb02-ldo11 {
				regulator-name = "S2MPB02_LDO11";
				regulator-min-microvolt = <2800000>;
				regulator-max-microvolt = <2800000>;
				regulator-always-on;
				regulator-boot-on;
			};

			_ldo12_reg: s2mpb02-ldo12 {
				regulator-name = "S2MPB02_LDO12";
				regulator-min-microvolt = <2800000>;
				regulator-max-microvolt = <2800000>;
			};

			_ldo13_reg: s2mpb02-ldo13 {
				regulator-name = "S2MPB02_LDO13";
				regulator-min-microvolt = <2900000>;
				regulator-max-microvolt = <2900000>;
			};

			_ldo14_reg: s2mpb02-ldo14 {
				regulator-name = "S2MPB02_LDO14";
				regulator-min-microvolt = <2800000>;
				regulator-max-microvolt = <2800000>;
			};

			_ldo15_reg: s2mpb02-ldo15 {
				regulator-name = "S2MPB02_LDO15";
				regulator-min-microvolt = <2800000>;
				regulator-max-microvolt = <2800000>;
			};

			_ldo16_reg: s2mpb02-ldo16 {
				regulator-name = "S2MPB02_LDO16";
				regulator-min-microvolt = <2800000>;
				regulator-max-microvolt = <2800000>;
			};

			_ldo17_reg: s2mpb02-ldo17 {
				regulator-name = "S2MPB02_LDO17";
				regulator-min-microvolt = <2950000>;
				regulator-max-microvolt = <2950000>;
			};

			_ldo18_reg: s2mpb02-ldo18 {
				regulator-name = "S2MPB02_LDO18";
				regulator-min-microvolt = <3300000>;
				regulator-max-microvolt = <3300000>;
				regulator-always-on;
				regulator-boot-on;
			};
		};
	};
};

/* USI_03_CMGP */
&usi_03_cmgp {
	usi_v2_mode = "spi";
	status = "okay";
};

&pinctrl_0 {
	key_voldown: key-voldown {
		samsung,pins = "gpa0-4";
		samsung,pin-function = <0xf>;
		samsung,pin-pud = <0>;
		samsung,pin-drv = <0>;
	};

	key_volup: key-volup {
		samsung,pins = "gpa0-3";
		samsung,pin-function = <0xf>;
		samsung,pin-pud = <0>;
		samsung,pin-drv = <0>;
	};

	key_power: key-power {
		samsung,pins = "gpa2-4";
		samsung,pin-function = <0xf>;
		samsung,pin-pud = <3>;
		samsung,pin-drv = <3>;
	};

	attn_irq: attn-irq {
		samsung,pins = "gpa1-0";
		samsung,pin-function = <0xf>;
		samsung,pin-pud = <3>;
		samsung,pin-drv = <3>;
	};

	attn_input: attn-input {
		samsung,pins = "gpa1-0";
		samsung,pin-function = <0>;
		samsung,pin-pud = <1>;
	};

	dwmmc2_cd_ext_irq: dwmmc2_cd_ext_irq {
		samsung,pins = "gpa3-4";
		samsung,pin-function = <0xf>;
		samsung,pin-pud = <3>;
		samsung,pin-drv = <4>;
	};

};

&pinctrl_1 {
	usbpd_irq: usbpd-irq {
		samsung,pins = "gpm17-0";
		samsung,pin-function = <0xf>;
		samsung,pin-pud = <0>;
		samsung,pin-drv = <0>;
	};
};

&panel_0 {
	/* reset, power */
	gpios = <&gpp5 6 0x1>, <&gpa1 2 0x1>;
};

&hsi2c_12 {
	#address-cells = <1>;
	#size-cells = <0>;
	status = "okay";
	samsung,reset-before-trans;
	touchscreen@48 {
		compatible = "sec,sec_ts";
		reg = <0x48>;
		pinctrl-names = "on_state", "off_state";
		pinctrl-0 = <&attn_irq>;
		pinctrl-1 = <&attn_input>;
		pressure-sensor = "Y";
		sec,irq_gpio = <&gpa1 0 0>;
		sec,irq_type = <8200>;
		sec,max_coords = <4095 4095>;
		sec,mis_cal_check = <1>;
		sec,regulator_dvdd = "S2MPB02_LDO6";
		sec,regulator_avdd = "S2MPB02_LDO18";
		sec,regulator_boot_on;
		sec,always_lpmode = <1>;
		sec,project_name = "2020";
		sec,firmware_name = "tsp_sec/y761_dream1.fw", "tsp_sec/y761_dream1.fw";
	};
};

&udc {
	status = "okay";
};

&usbdrd_dwc3 {
	status = "okay";

	dr_mode = "otg";
	maximum-speed = "super-speed-plus";
	snps,quirk-frame-length-adjustment = <0x20>;
	snps,u1u2_exitfail_quirk;
	/* ux_exit_in_px should be defined in MK, LT */
	snps,ux_exit_in_px_quirk;
	/* elastic_buf_mode_quirk should be defined in MK */
	snps,elastic_buf_mode_quirk;
	/* usb3-lpm-capable; */
	/* snps,usb3_lpm_capable; */
	/*
	 * dis-u2-freeclk-exists-quirk, dis_u2_susphy_quirk are alternative.
	 * One of them should be selected
	 */
	snps,dis-u2-freeclk-exists-quirk;
	/*snps,dis_u2_susphy_quirk;*/

	usb_audio_offloading = <0>;
	/* abox = <&abox>;  Temporary block */
	/* check susphy support */
	xhci_l2_support = <0>;
};

&usbdrd_phy0 {
	status = "okay";
	use_default_tune_val = <0x1>;

	pinctrl-names = "default";
	/* pinctrl-0 = <&phy_port>; */
	/* phy,gpio_phy_port = <&gpg0 4 0x0>; */
	hs_tune_param = <&usb_hs_tune>;
	ss_tune_param = <&usb_ss_tune>;
};

&dwmmc_2 {
	#address-cells = <1>;
	#size-cells = <0>;
	status = "okay";
	num-slots = <1>;
	supports-4bit;
	supports-cmd23;
	supports-erase;
	supports-highspeed;
	sd-uhs-sdr50;
	sd-uhs-sdr104;
	card-detect-gpio;
	bypass-for-allpass;
	use-fine-tuning;
	card-init-hwacg-ctrl;
	skip-init-mmc-scan;
	fifo-depth = <0x40>;
	qos_dvfs_level = <400000>;
	desc-size = <4>;
	card-detect-delay = <200>;
	data-timeout = <200>;
	hto-timeout = <80>;
	samsung,dw-mshc-ciu-div = <3>;
	clock-frequency = <800000000>;
	samsung,dw-mshc-sdr-timing = <3 0 2 0>;
	samsung,dw-mshc-ddr-timing = <3 0 2 1>;
	samsung,dw-mshc-sdr50-timing = <3 0 4 2>;
	samsung,dw-mshc-sdr104-timing = <3 0 3 0>;

	num-ref-clks = <9>;
	ciu_clkin = <25 50 50 25 50 100 200 50 50>;

	/* Swapping clock drive strength */
	clk-drive-number = <6>;
	pinctrl-names = "default",
		"fast-slew-rate-1x",
		"fast-slew-rate-1_5x",
		"fast-slew-rate-2x",
		"fast-slew-rate-2_5x",
		"fast-slew-rate-3x",
		"fast-slew-rate-4x",
		"pins-as-pdn",
		"pins-as-func";
	pinctrl-0 = <&sd2_clk &sd2_cmd &sd2_bus1 &sd2_bus4 &dwmmc2_cd_ext_irq>;
	pinctrl-1 = <&sd2_clk_fast_slew_rate_1x>;
	pinctrl-2 = <&sd2_clk_fast_slew_rate_1_5x>;
	pinctrl-3 = <&sd2_clk_fast_slew_rate_2x>;
	pinctrl-4 = <&sd2_clk_fast_slew_rate_2_5x>;
	pinctrl-5 = <&sd2_clk_fast_slew_rate_3x>;
	pinctrl-6 = <&sd2_clk_fast_slew_rate_4x>;
	pinctrl-7 = <&sd2_pins_as_pdn>;
	pinctrl-8 = <&sd2_clk &sd2_cmd &sd2_bus1 &sd2_bus4>;

	card-detect = <&gpa3 4 0xf>;
	slot@0 {
		reg = <0>;
		bus-width = <4>;
		disable-wp;
	};
};

&pcie_0 {
	status = "okay";
	use-sysmmu = "false";
	use-cache-coherency = "false";
	use-msi = "false";
	ep-device-type = <EP_BCM_WIFI>;
	pcie,wlan-gpio = <&gpm22 0 0x1 /* WLAN_EN */ >;
};

&pcie_1 {
	status = "okay";
	use-sysmmu = "false";
	use-cache-coherency = "false";
	use-msi = "false";
	use-sicd = "false";
	phy-power-off = "false";
	pcie,ssd-gpio = <&gpa1 5 0x1 /* PCIE_VDD_3V3_EN */>;
};

&pcie_2 {
	status = "okay";
	use-sysmmu = "false";
	use-cache-coherency = "true";
	use-msi = "true";
	use-sicd = "false";
	phy-power-off = "false";
	ep-device-type = <EP_SAMSUNG_MODEM>;
};

&hsi2c_37 {
	#address-cells = <1>;
	#size-cells = <0>;
	status = "okay";
	s2mu106@3d {
		compatible = "samsung,s2mu106mfd";
		reg = <0x3d>;
		pinctrl-names = "default";
		pinctrl-0 = <&if_pmic_irq>;
		s2mu106,irq-gpio = <&gpa2 0 0>;
		s2mu106,wakeup;
	};

	muic {
		status = "okay";
		compatible = "samsung,s2mu106-muic";
	};

	ifconn {
		status = "okay";
		compatible = "samsung,ifconn";
		ifconn,usbpd = "s2mu106";
		ifconn,muic = "s2mu106-muic";
	};
};

&ufs {
	/* board type for UFS CAL */
	brd-for-cal = /bits/ 8 <1>;  /* (1:SMDK, 16:UNIV) board */
};

&pinctrl_1 {
	codec_reset: codec-reset {
		samsung,pins ="gpm32-0";
		samsung,pin-con-pdn =<3>;
		samsung,pin-pud-pdn = <1>;
	};
};

&spi_11 {
	#address-cells = <1>;
	#size-cells = <0>;
	status = "okay";
	pinctrl-names = "default";
	pinctrl-0 = <&spi11_bus &spi11_cs_func>;

	cs47l93: cs47l93@0 {
		compatible = "cirrus,cs47l93";
		reg = <0x0>;

		spi-max-frequency = <10000000>;

		interrupt-parent = <&gpa2>;
		interrupts = <2 0 0>;
		interrupt-controller;
		#interrupt-cells = <2>;
		gpio-controller;
		#gpio-cells = <2>;
		#sound-dai-cells = <1>;

		AVDD-supply = <&ldo17_reg>;
		DBVDD1-supply = <&ldo17_reg>;
		CPVDD1-supply = <&ldo17_reg>;
		CPVDD2-supply = <&ldo18_reg>;
		DCVDD-supply = <&ldo18_reg>;

		reset-gpios = <&gpm32 0 0>;

		cirrus,dmic-ref = <0 1 1 1>;
		cirrus,inmode = < /* 0: diff 1: single 2: dmic */
			1 1 2 2 /* IN1 */
			2 2 2 2 /* IN2 */
		>;
		cirrus,out-mono = <0 0 1 1 0 0>;
		cirrus,gpsw = <1 0>;

		pinctrl-names = "default";
		pinctrl-0 = <&codec_reset &cs47l93_defaults>;

		cs47l93_defaults: cs47l93-gpio-defaults {
			aif1 {
				groups = "aif1";
				function = "aif1";
				bias-bus-hold;
			};

			gpio9 {
				groups = "gpio9";
				function = "io";
				bias-disable;
				drive-strength = <8>;
			};

			gpio10 {
				groups = "gpio10";
				function = "io";
				bias-disable;
				drive-strength = <8>;
			};

			aif3 {
				groups = "aif3";
				function = "aif3";
				bias-bus-hold;
			};
		};

		micvdd {
			regulator-min-microvolt = <3000000>;
			regulator-max-microvolt = <3000000>;
		};

		MICBIAS1 {
			regulator-min-microvolt = <1800000>;
			regulator-max-microvolt = <1800000>;
			cirrus,ext-cap = <1>;
		};
		MICBIAS1A {
			regulator-active-discharge = <1>;
		};
		MICBIAS1B {
			regulator-active-discharge = <1>;
		};
		MICBIAS1C {
			regulator-active-discharge = <1>;
		};
		MICBIAS1D {
			regulator-active-discharge = <1>;
		};
		MICBIAS2 {
			regulator-min-microvolt = <2800000>;
			regulator-max-microvolt = <2800000>;
			cirrus,ext-cap = <1>;
		};
		MICBIAS2A {
			regulator-active-discharge = <1>;
		};

		cirrus,accdet {
			#address-cells = <1>;
			#size-cells = <0>;

			acc@1 {
				reg = <1>;

				cirrus,micd-bias-start-time = <0x1>;
				cirrus,micd-rate = <7>;
				cirrus,micd-detect-debounce-ms = <300>;
				cirrus,micd-clamp-mode = <0x8>;
				cirrus,jd-use-jd2;

				cirrus,init-delay-ms = <30>;
				cirrus,micd-dbtime = <0x1>;
				cirrus,micd-timeout-ms = <1000>;
				cirrus,micd-force-micbias;
				cirrus,hpdet-short-circuit-imp = <3>;
				cirrus,micd-ranges = <
					116 226
					173 582
					321 115
					752 114
					1257 217
				>;
				cirrus,micd-software-compare;
				cirrus,micd-open-circuit-declare = <1>;
				cirrus,jd-wake-time = <5000>;

				cirrus,micd-configs = <
					0 1 4 0 1
				>;
			};
		};

		controller-data {
			samsung,spi-feedback-delay = <1>;
			samsung,spi-chip-select-mode = <0>;
		};
	};
};

&abox_uaif_4 {
	pinctrl-names;
};

&hsi2c_8 {
	status = "okay";
	#address-cells = <1>;
	#size-cells = <0>;
	tfa9874: tfa9874@34 {
		compatible = "nxp,tfa9874";
		#sound-dai-cells = <1>;
		reg = <0x34>;
	};
};

&hsi2c_4 {
	#address-cells = <1>;
	#size-cells = <0>;
	status = "okay";
	usbpd-s2mu106@3C {
		compatible = "sec-usbpd,i2c";
		reg = <0x3C>;
		pinctrl-names = "default";
		pinctrl-0 = <&usbpd_irq>;
		usbpd,usbpd_int = <&gpm17 0 0>;

		pdic-manager {
			/* sink */
			pdic,max_power = <5000>;
			pdic,op_power = <2500>;
			pdic,max_voltage = <6000>;
			pdic,max_current = <2000>;
			pdic,min_current = <500>;

			pdic,giveback = <0>;
			pdic,usb_com_capable = <1>;
			pdic,no_usb_suspend = <1>;

			/* source */
			source,max_voltage = <5000>;
			source,min_voltage = <4000>;
			source,max_power = <2500>;

			/* sink cap */
			sink,capable_max_voltage = <5000>;
		};
	};
};
